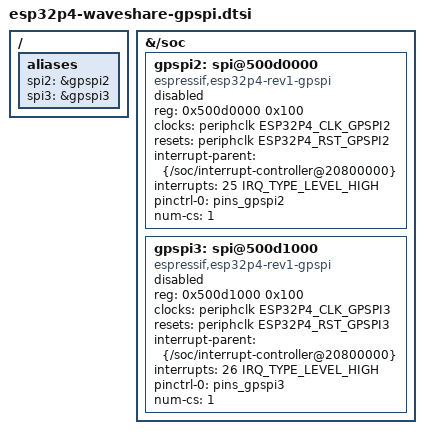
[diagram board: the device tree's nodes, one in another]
// SPDX-License-Identifier: (GPL-2.0-only OR BSD-2-Clause)
#include <dt-bindings/interrupt-controller/irq.h>

/ {
	aliases {
		spi2 = &gpspi2;
		spi3 = &gpspi3;
	};
};

&{/soc} {
	/* TRM ch.47 SPI Controller and ch.14 Interrupt Matrix — SPI2/3. */
	/* P6 GPIO20..23. No implicit spidev or external device. */
	gpspi2: spi@500d0000 {
		compatible = "espressif,esp32p4-rev1-gpspi";
		reg = <0x500d0000 0x100>;
		clocks = <&periphclk ESP32P4_CLK_GPSPI2>;
		resets = <&periphclk ESP32P4_RST_GPSPI2>;
		interrupt-parent = <&{/soc/interrupt-controller@20800000}>;
		interrupts = <25 IRQ_TYPE_LEVEL_HIGH>;
		pinctrl-0 = <&pins_gpspi2>;
		pinctrl-names = "default";
		num-cs = <1>;
		#address-cells = <1>;
		#size-cells = <0>;
		status = "disabled";
	};

	/* P6 GPIO20..23. No implicit spidev or external device. */
	gpspi3: spi@500d1000 {
		compatible = "espressif,esp32p4-rev1-gpspi";
		reg = <0x500d1000 0x100>;
		clocks = <&periphclk ESP32P4_CLK_GPSPI3>;
		resets = <&periphclk ESP32P4_RST_GPSPI3>;
		interrupt-parent = <&{/soc/interrupt-controller@20800000}>;
		interrupts = <26 IRQ_TYPE_LEVEL_HIGH>;
		pinctrl-0 = <&pins_gpspi3>;
		pinctrl-names = "default";
		num-cs = <1>;
		#address-cells = <1>;
		#size-cells = <0>;
		status = "disabled";
	};
};
